# STM32F765BGT6 register map
File version: 1.0
Registers are 32-bit, access not given, reset 0x0 unless marked. A register's access mark holds for its fields unless they carry their own. Offsets are from the block's base; [hi:lo] are bit positions; {n}, {i} and the like mark numbered series; 'fields as' and 'values as' point back to an identical list.

## SYSCFG
Base 0x40013800
0x00 MEMRMP
  [11:10] SWP_FMC, [8] SWP_FB, [31:1] s, [0] MEM_BOOT
0x04 PMC
  [23] MII_RMII_SEL, [18] ADC3DC2, [17] ADC2DC2, [16] ADC1DC2, [31:8] s, [n-2] PB{n}_FMP (n=6..9), [n-1] I2C{n}_FB (n=1..4)
{0x4+4i} EXTICR{i} (i=1..4)
0x1C CBR
0x20 CMPCR

## EXTI
Base 0x40013C00
0x00 IMR
0x04 EMR
0x08 RTSR
0x0C FTSR
0x10 SWIER
0x14 PR

## SAI1
Base 0x40015800
Same registers: SAI2 0x40015C00
0x00 GCR
  [5:4] SYNCOUT, [31:2] s, [1:0] SYNCIN
0x04 CR1A
  [23:20] MCKDIV, [19] NODIV, [17] DMAEN, [16] SAIEN, [13] OUTDRIV, [12] MONO, [11:10] SYNCEN, [9] CKSTR, [8] LSBFIRST, [7:5] DS, [31:4] s, [3:2] PRTCFG, [1:0] MODE
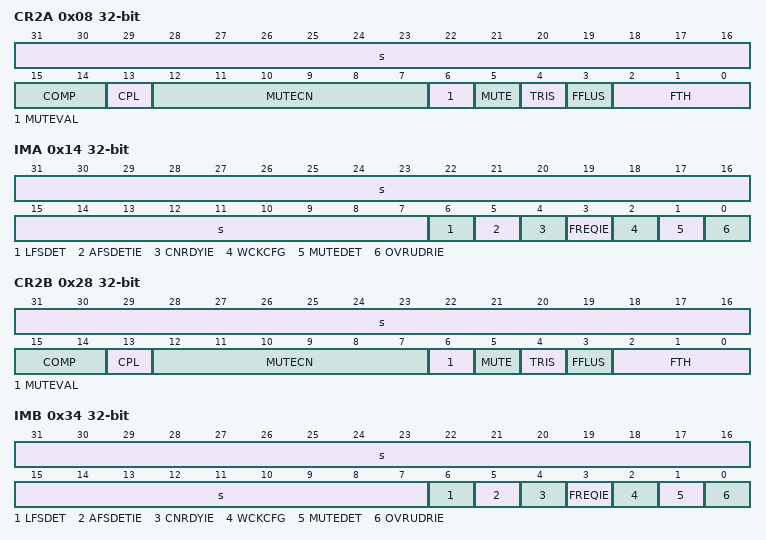
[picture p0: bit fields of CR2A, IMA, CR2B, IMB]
0x08 CR2A
  [31:16] s, [15:14] COMP, [13] CPL, [12:7] MUTECN, [6] MUTEVAL, [5] MUTE, [4] TRIS, [3] FFLUS, [2:0] FTH
0x0C FRCRA
  [18] FSOFF, [17] FSPOL, [16] FSDEF, [31:15] s, [14:8] FSALL, [7:0] FRL
0x10 SLOTRA
  [31:16] SLOTEN, [11:8] NBSLOT, [7:6] SLOTSZ}, [15:5] s, [4:0] FBOFF
0x14 IMA
  [31:7] s, [6] LFSDET, [5] AFSDETIE, [4] CNRDYIE, [3] FREQIE, [2] WCKCFG, [1] MUTEDET, [0] OVRUDRIE
0x18 SRA
  [18:16] FLVL, [31:7] s, [6] LFSDET, [5] AFSDET, [4] CNRDY, [3] FREQ, [2] WCKCFG, [1] MUTEDET, [0] OVRUDR
0x1C CLRFRA
  [6] LFSDET, [5] CAFSDET, [4] CNRDY, [31:3] s, [2] WCKCFG, [1] MUTEDET, [0] OVRUDR
0x20 DRA
  [31:0] DATA
0x24 CR1B
  fields as CR1A
0x28 CR2B
  fields as CR2A
0x2C FRCRB
  fields as FRCRA
0x30 SLOTRB
  [31:16] SLOTEN, [11:8] NBSLOT, [7:6] SLOTSZ}, [15:5] s, [4:0] FBOFF
0x34 IMB
  fields as IMA
0x38 SRB
  fields as SRA
0x3C CLRFRB
  fields as CLRFRA
0x40 DRB
  [31:0] DATA

## LTDC
Base 0x40016800
0x08 SSCR
  [27:16] HSW, [31:11] s, [10:0] VSH
0x0C BPCR
  [27:16] AHBP, [31:11] s, [10:0] AVBP
0x10 AWCR
  [27:16] AAW, [31:11] s, [10:0] AAH
0x14 TWCR
  [27:16] TOTALW, [31:11] s, [10:0] TOTALH
0x18 GCR
  [31] HSPOL, [30] VSPOL, [29] DEPOL, [28] PCPOL, [16] DEN, [14:12] DRW, [10:8] DGW, [6:4] DBW, [27:1] s, [0] LTDCEN
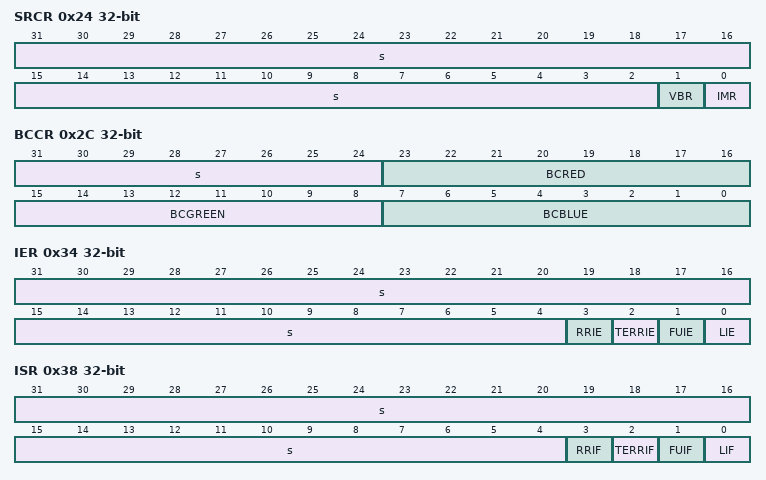
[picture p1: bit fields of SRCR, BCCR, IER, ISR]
0x24 SRCR
  [31:2] s, [1] VBR, [0] IMR
0x2C BCCR
  [31:24] s, [23:16] BCRED, [15:8] BCGREEN, [7:0] BCBLUE
0x34 IER
  [31:4] s, [3] RRIE, [2] TERRIE, [1] FUIE, [0] LIE
0x38 ISR
  [31:4] s, [3] RRIF, [2] TERRIF, [1] FUIF, [0] LIF
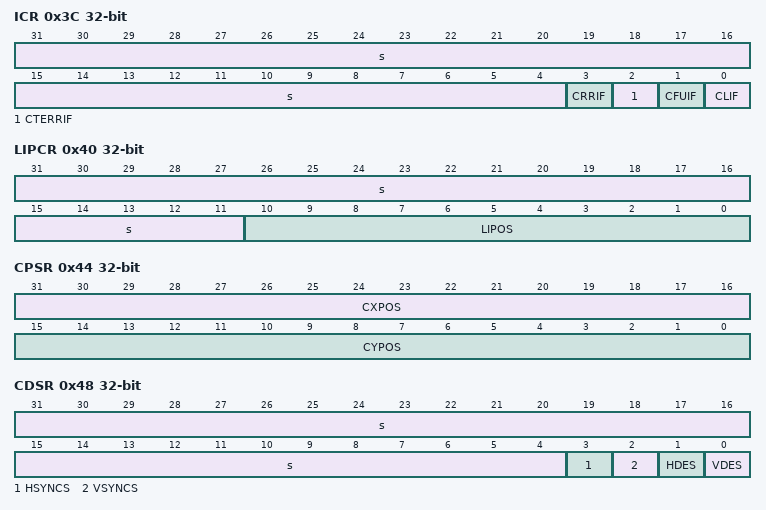
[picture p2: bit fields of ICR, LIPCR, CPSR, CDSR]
0x3C ICR
  [31:4] s, [3] CRRIF, [2] CTERRIF, [1] CFUIF, [0] CLIF
0x40 LIPCR
  [31:11] s, [10:0] LIPOS
0x44 CPSR
  [31:16] CXPOS, [15:0] CYPOS
0x48 CDSR
  [31:4] s, [3] HSYNCS, [2] VSYNCS, [1] HDES, [0] VDES
0x84 L1CR
  [4] CLUTEN, [31:2] s, [1] COLKEN, [0] LEN
0x88 L1WHPCR
  [27:16] WHSPPOS, [31:12] s, [11:0] WHSTPOS
0x8C L1WVPCR
  [26:16] WVSPPOS, [31:11] s, [10:0] WVSTPOS
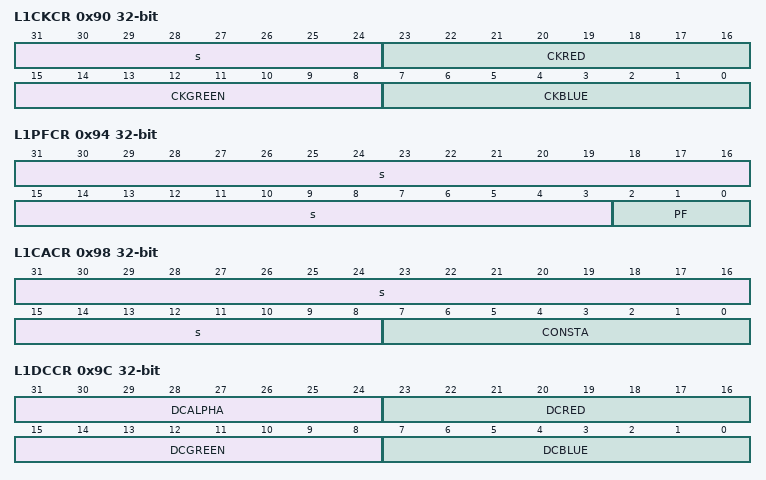
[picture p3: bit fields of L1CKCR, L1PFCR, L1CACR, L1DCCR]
0x90 L1CKCR
  [31:24] s, [23:16] CKRED, [15:8] CKGREEN, [7:0] CKBLUE
0x94 L1PFCR
  [31:3] s, [2:0] PF
0x98 L1CACR
  [31:8] s, [7:0] CONSTA
0x9C L1DCCR
  [31:24] DCALPHA, [23:16] DCRED, [15:8] DCGREEN, [7:0] DCBLUE
0xA0 L1BFCR
  [10:8] BF1, [31:3] s, [2:0] BF2
0xAC L1CFBAR
  [31:0] CFBADD
0xB0 L1CFBLR
  [28:16] CFBP, [31:13] s, [12:0] CFBLL
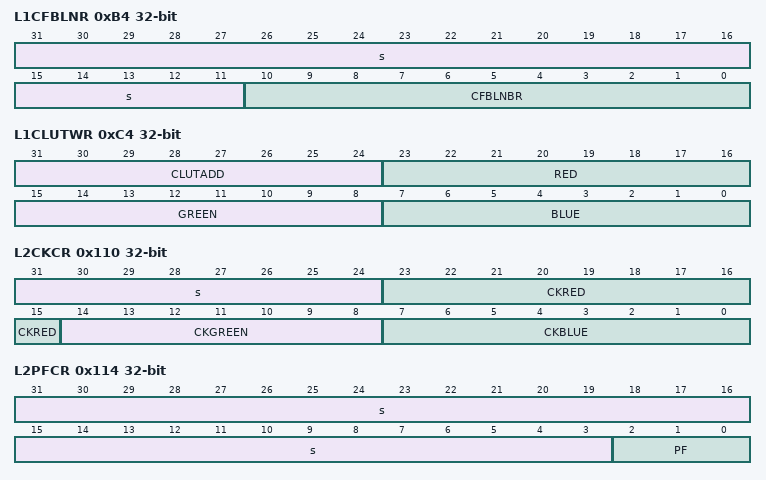
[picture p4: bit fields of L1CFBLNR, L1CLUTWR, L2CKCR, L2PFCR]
0xB4 L1CFBLNR
  [31:11] s, [10:0] CFBLNBR
0xC4 L1CLUTWR
  [31:24] CLUTADD, [23:16] RED, [15:8] GREEN, [7:0] BLUE
0x104 L2CR
  [4] CLUTEN, [31:2] s, [1] COLKEN, [0] LEN
0x108 L2WHPCR
  [27:16] WHSPPOS, [31:12] s, [11:0] WHSTPOS
0x10C L2WVPCR
  [26:16] WVSPPOS, [31:11] s, [10:0] WVSTPOS
0x110 L2CKCR
  [31:24] s, [23:15] CKRED, [14:8] CKGREEN, [7:0] CKBLUE
0x114 L2PFCR
  [31:3] s, [2:0] PF
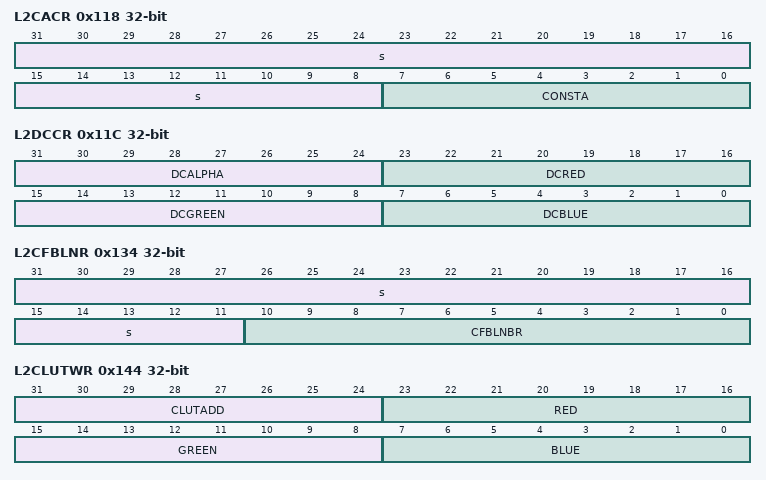
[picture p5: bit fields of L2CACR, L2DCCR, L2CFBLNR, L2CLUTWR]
0x118 L2CACR
  [31:8] s, [7:0] CONSTA
0x11C L2DCCR
  [31:24] DCALPHA, [23:16] DCRED, [15:8] DCGREEN, [7:0] DCBLUE
0x120 L2BFCR
  [10:8] BF1, [31:3] s, [2:0] BF2
0x12C L2CFBAR
  [31:0] CFBADD
0x130 L2CFBLR
  [28:16] CFBP, [31:13] s, [12:0] CFBLL
0x134 L2CFBLNR
  [31:11] s, [10:0] CFBLNBR
0x144 L2CLUTWR
  [31:24] CLUTADD, [23:16] RED, [15:8] GREEN, [7:0] BLUE

## DFSDM1
Base 0x40017400
0x00 CH0CFGR1
  [31] DFSDMEN, [30] CKOUTSRC, [23:16] CKOUTDIV, [15:14] DATPACK, [13:12] DATMPX, [8] CHINSEL, [7] CHEN, [6] CKABEN, [5] SCDEN, [29:4] s, [3:2] SPICKSEL, [1:0] SITP
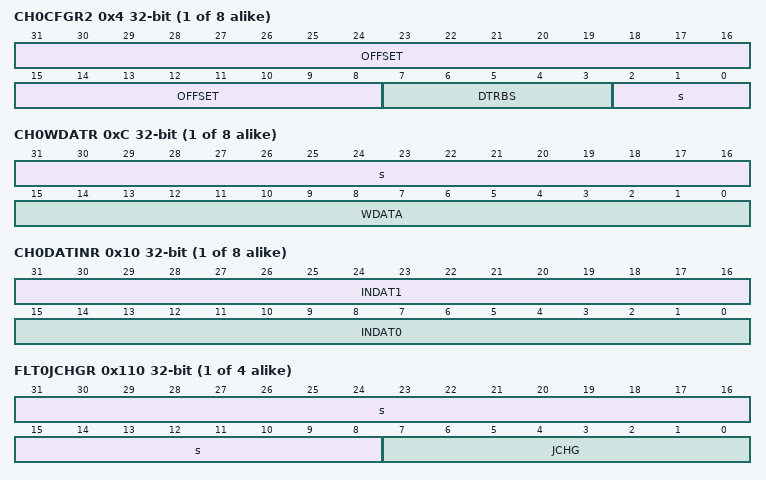
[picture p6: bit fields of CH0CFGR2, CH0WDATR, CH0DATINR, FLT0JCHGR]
{0x4+0x20*i} CH{i}CFGR2 (i=0..7)
  [31:8] OFFSET, [7:3] DTRBS, [2:0] s
{0x8+0x20*i} CH{i}AWSCDR (i=0..7)
  [23:22] AWFORD, [20:16] AWFOSR, [15:12] BKSCD, [31:8] s, [7:0] SCDT
{0xC+0x20*i} CH{i}WDATR (i=0..7)
  [31:16] s, [15:0] WDATA
{0x10+0x20*i} CH{i}DATINR (i=0..7)
  [31:16] INDAT1, [15:0] INDAT0
{0x0+0x20*i} CH{i}CFGR1 (i=1..7)
  [15:14] DATPACK, [13:12] DATMPX, [8] CHINSEL, [7] CHEN, [6] CKABEN, [5] SCDEN, [31:4] s, [3:2] SPICKSEL, [1:0] SITP
{0x100+0x80*i} FLT{i}CR1 (i=0..3)
  [30] AWFSEL, [29] FAST, [26:24] RCH, [21] RDMAEN, [19] RSYNC, [18] RCONT, [17] RSWSTART, [14:13] JEXTEN, [12:8] JEXTSEL, [5] JDMAEN, [4] JSCAN, [3] JSYNC, [31:2] s, [1] JSWSTART, [0] DFEN
0x104 FLT0CR2
  [23:16] AWDCH, [15:8] EXCH, [31:7] s, [6] CKABIE, [5] SCDIE, [4] AWDIE, [3] ROVRIE, [2] JOVRIE, [1] REOCIE, [0] JEOCIE
0x108 FLT0ISR
  [31:24] SCDF, [23:16] CKABF, [14] RCIP, [13] JCIP, [15:5] s, [4] AWDF, [3] ROVRF, [2] JOVRF, [1] REOCF, [0] JEOCF
0x10C FLT0ICR
  [31:24] CLRSCDF, [23:16] CLRCKABF, [3] CLRROVRF, [2] CLRJOVRF, [15:0] s
{0x110+0x80*i} FLT{i}JCHGR (i=0..3)
  [31:8] s, [7:0] JCHG
{0x114+0x80*i} FLT{i}FCR (i=0..3)
  [31:29] FORD, [25:16] FOSR, [28:8] s, [7:0] IOSR
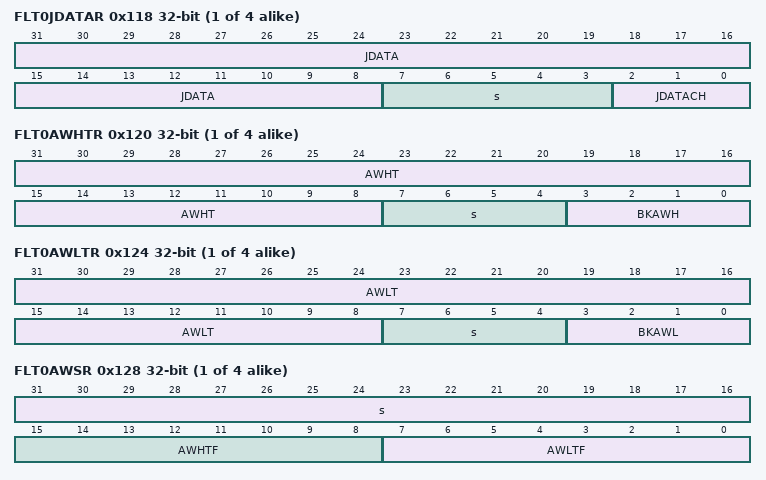
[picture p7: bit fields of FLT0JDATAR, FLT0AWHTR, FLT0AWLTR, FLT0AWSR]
{0x118+0x80*i} FLT{i}JDATAR (i=0..3)
  [31:8] JDATA, [7:3] s, [2:0] JDATACH
{0x11C+0x80*i} FLT{i}RDATAR (i=0..3)
  [31:8] RDATA, [4] RPEND, [7:3] s, [2:0] RDATACH
{0x120+0x80*i} FLT{i}AWHTR (i=0..3)
  [31:8] AWHT, [7:4] s, [3:0] BKAWH
{0x124+0x80*i} FLT{i}AWLTR (i=0..3)
  [31:8] AWLT, [7:4] s, [3:0] BKAWL
{0x128+0x80*i} FLT{i}AWSR (i=0..3)
  [31:16] s, [15:8] AWHTF, [7:0] AWLTF
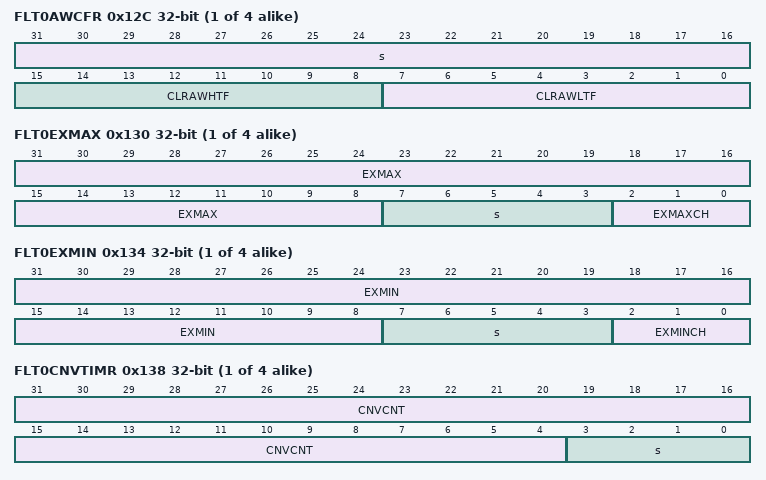
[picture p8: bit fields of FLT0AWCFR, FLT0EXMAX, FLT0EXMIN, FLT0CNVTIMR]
{0x12C+0x80*i} FLT{i}AWCFR (i=0..3)
  [31:16] s, [15:8] CLRAWHTF, [7:0] CLRAWLTF
{0x130+0x80*i} FLT{i}EXMAX (i=0..3)
  [31:8] EXMAX, [7:3] s, [2:0] EXMAXCH
{0x134+0x80*i} FLT{i}EXMIN (i=0..3)
  [31:8] EXMIN, [7:3] s, [2:0] EXMINCH
{0x138+0x80*i} FLT{i}CNVTIMR (i=0..3)
  [31:4] CNVCNT, [3:0] s
{0x104+0x80*i} FLT{i}CR2 (i=1..3)
  [23:16] AWDCH, [15:8] EXCH, [31:5] s, [4] AWDIE, [3] ROVRIE, [2] JOVRIE, [1] REOCIE, [0] JEOCIE
{0x108+0x80*i} FLT{i}ISR (i=1..3)
  [14] RCIP, [13] JCIP, [31:5] s, [4] AWDF, [3] ROVRF, [2] JOVRF, [1] REOCF, [0] JEOCF
{0x10C+0x80*i} FLT{i}ICR (i=1..3)
  [3] CLRROVRF, [2] CLRJOVRF, [31:0] s
